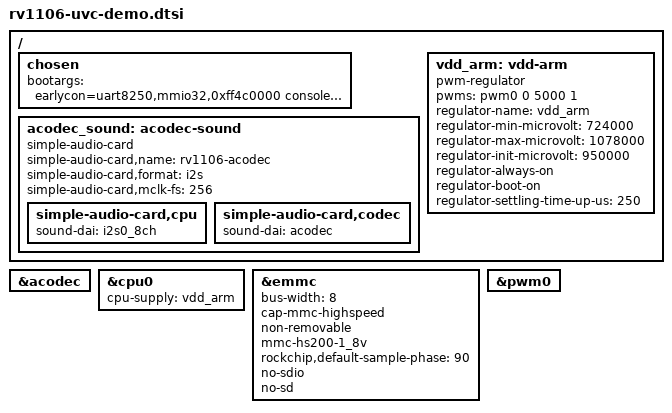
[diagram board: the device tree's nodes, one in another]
// SPDX-License-Identifier: (GPL-2.0+ OR MIT)
/*
 * Copyright (c) 2022 Rockchip Electronics Co., Ltd.
 */

#include "rv1106-uvc.dtsi"
#include "rv1106-evb-cam.dtsi"

/ {
	chosen {
		bootargs = "earlycon=uart8250,mmio32,0xff4c0000 console=ttyFIQ0 root=/dev/mmcblk0p5 rootfstype=ext4 rootwait snd_soc_core.prealloc_buffer_size_kbytes=16";
	};

	acodec_sound: acodec-sound {
		compatible = "simple-audio-card";
		simple-audio-card,name = "rv1106-acodec";
		simple-audio-card,format = "i2s";
		simple-audio-card,mclk-fs = <256>;
		simple-audio-card,cpu {
			sound-dai = <&i2s0_8ch>;
		};
		simple-audio-card,codec {
			sound-dai = <&acodec>;
		};
	};

	vdd_arm: vdd-arm {
		compatible = "pwm-regulator";
		pwms = <&pwm0 0 5000 1>;
		regulator-name = "vdd_arm";
		regulator-min-microvolt = <724000>;
		regulator-max-microvolt = <1078000>;
		regulator-init-microvolt = <950000>;
		regulator-always-on;
		regulator-boot-on;
		regulator-settling-time-up-us = <250>;
	};
};

&acodec {
	#sound-dai-cells = <0>;
	//pa-ctl-gpios = <&gpio1 RK_PA1 GPIO_ACTIVE_HIGH>;
	status = "okay";
};

&cpu0 {
	cpu-supply = <&vdd_arm>;
};

&emmc {
	bus-width = <8>;
	cap-mmc-highspeed;
	non-removable;
	mmc-hs200-1_8v;
	rockchip,default-sample-phase = <90>;
	no-sdio;
	no-sd;
	status = "okay";
};

&pwm0 {
	status = "okay";
};

